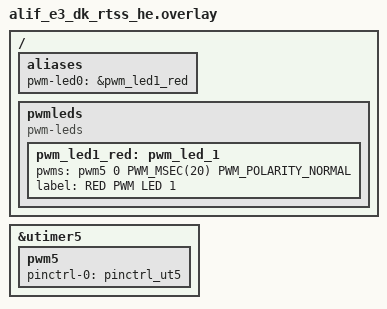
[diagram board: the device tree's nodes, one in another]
/* Copyright (c) 2025 Alif Semiconductor
 *
 * SPDX-License-Identifier: Apache-2.0
 */

/ {
	aliases {
		pwm-led0 = &pwm_led1_red;
	};

	pwmleds {
		compatible = "pwm-leds";
		pwm_led1_red: pwm_led_1 {
			pwms = <&pwm5 0 PWM_MSEC(20) PWM_POLARITY_NORMAL>;
			label = "RED PWM LED 1";
		};
	};
};

&utimer5 {
	status = "okay";

	pwm5: pwm5 {
		pinctrl-0 = <&pinctrl_ut5>;
		pinctrl-names = "default";
		status = "okay";
	};
};
